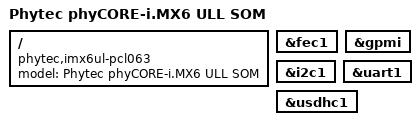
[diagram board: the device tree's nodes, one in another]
/*
 * Copyright (C) 2017 PHYTEC Messtechnik GmbH
 * Author: Stefan Riedmueller <s.riedmueller@phytec.de>
 *
 * The code contained herein is licensed under the GNU General Public
 * License. You may obtain a copy of the GNU General Public License
 * Version 2 or later at the following locations:
 *
 * http://www.opensource.org/licenses/gpl-license.html
 * http://www.gnu.org/copyleft/gpl.html
 */

/dts-v1/;

#include <arm/imx6ull.dtsi>
#include "imx6ul-phytec-phycore-som.dtsi"

/ {
	model = "Phytec phyCORE-i.MX6 ULL SOM";
	compatible = "phytec,imx6ul-pcl063", "fsl,imx6ull";
};

&fec1 {
	status = "okay";
};

&gpmi {
	status = "okay";
};

&i2c1 {
	status = "okay";
};

&uart1 {
	status = "okay";
};

&usdhc1 {
	status = "okay";
};
